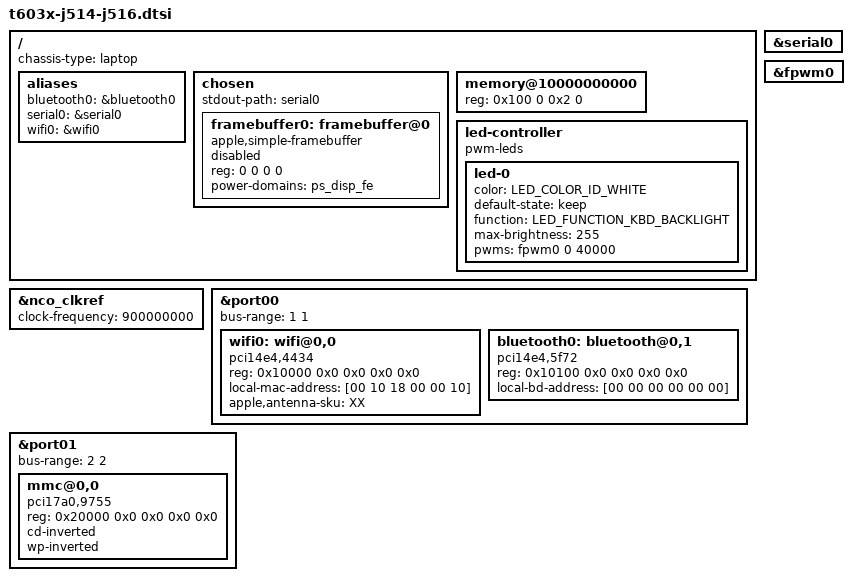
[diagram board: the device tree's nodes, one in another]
// SPDX-License-Identifier: GPL-2.0+ OR MIT
/*
 * MacBook Pro (14/16-inch, 2023)
 *
 * This file contains the parts common to J514 and J516 devices with t6030,
 * t6031 and t6034.
 *
 * target-type: J514s / J514m / J514c / J516s / J516m / J516c
 *
 * Copyright The Asahi Linux Contributors
 */

/*
 * These models are essentially identical to the previous generations, other
 * than the GPIO indices and using SPMI based USB Type-C port controllers.
 */

#include <dt-bindings/leds/common.h>

/ {
	chassis-type = "laptop";

	aliases {
		bluetooth0 = &bluetooth0;
		serial0 = &serial0;
		wifi0 = &wifi0;
	};

	chosen {
		ranges;
		#address-cells = <2>;
		#size-cells = <2>;

		stdout-path = "serial0";

		framebuffer0: framebuffer@0 {
			compatible = "apple,simple-framebuffer",
				     "simple-framebuffer";
			reg = <0 0 0 0>; /* To be filled by loader */
			/* Format properties will be added by loader */
			power-domains = <&ps_disp_fe>;

			status = "disabled";
		};
	};

	memory@10000000000 {
		device_type = "memory";
		reg = <0x100 0 0x2 0>; /* To be filled by loader */
	};

	led-controller {
		compatible = "pwm-leds";

		led-0 {
			color = <LED_COLOR_ID_WHITE>;
			default-state = "keep";
			function = LED_FUNCTION_KBD_BACKLIGHT;
			max-brightness = <255>;
			pwms = <&fpwm0 0 40000>;
		};
	};
};

&serial0 {
	status = "okay";
};

&fpwm0 {
	status = "okay";
};

&nco_clkref {
	clock-frequency = <900000000>;
};

/* PCIe devices */

/*
 * Force the bus number assignments so that we can declare some of the
 * on-board devices and properties that are populated by the bootloader
 * (such as MAC addresses).
 */
&port00 {
	/* WLAN */
	bus-range = <1 1>;

	wifi0: wifi@0,0 {
		compatible = "pci14e4,4434";
		reg = <0x10000 0x0 0x0 0x0 0x0>;
		/* To be filled by the loader */
		local-mac-address = [00 10 18 00 00 10];
		apple,antenna-sku = "XX";
	};

	bluetooth0: bluetooth@0,1 {
		compatible = "pci14e4,5f72";
		reg = <0x10100 0x0 0x0 0x0 0x0>;
		/* To be filled by the loader */
		local-bd-address = [00 00 00 00 00 00];
	};
};

&port01 {
	/* SD card reader */
	bus-range = <2 2>;

	mmc@0,0 {
		compatible = "pci17a0,9755";
		reg = <0x20000 0x0 0x0 0x0 0x0>;
		cd-inverted;
		wp-inverted;
	};
};

#include "spi1-nvram.dtsi"
